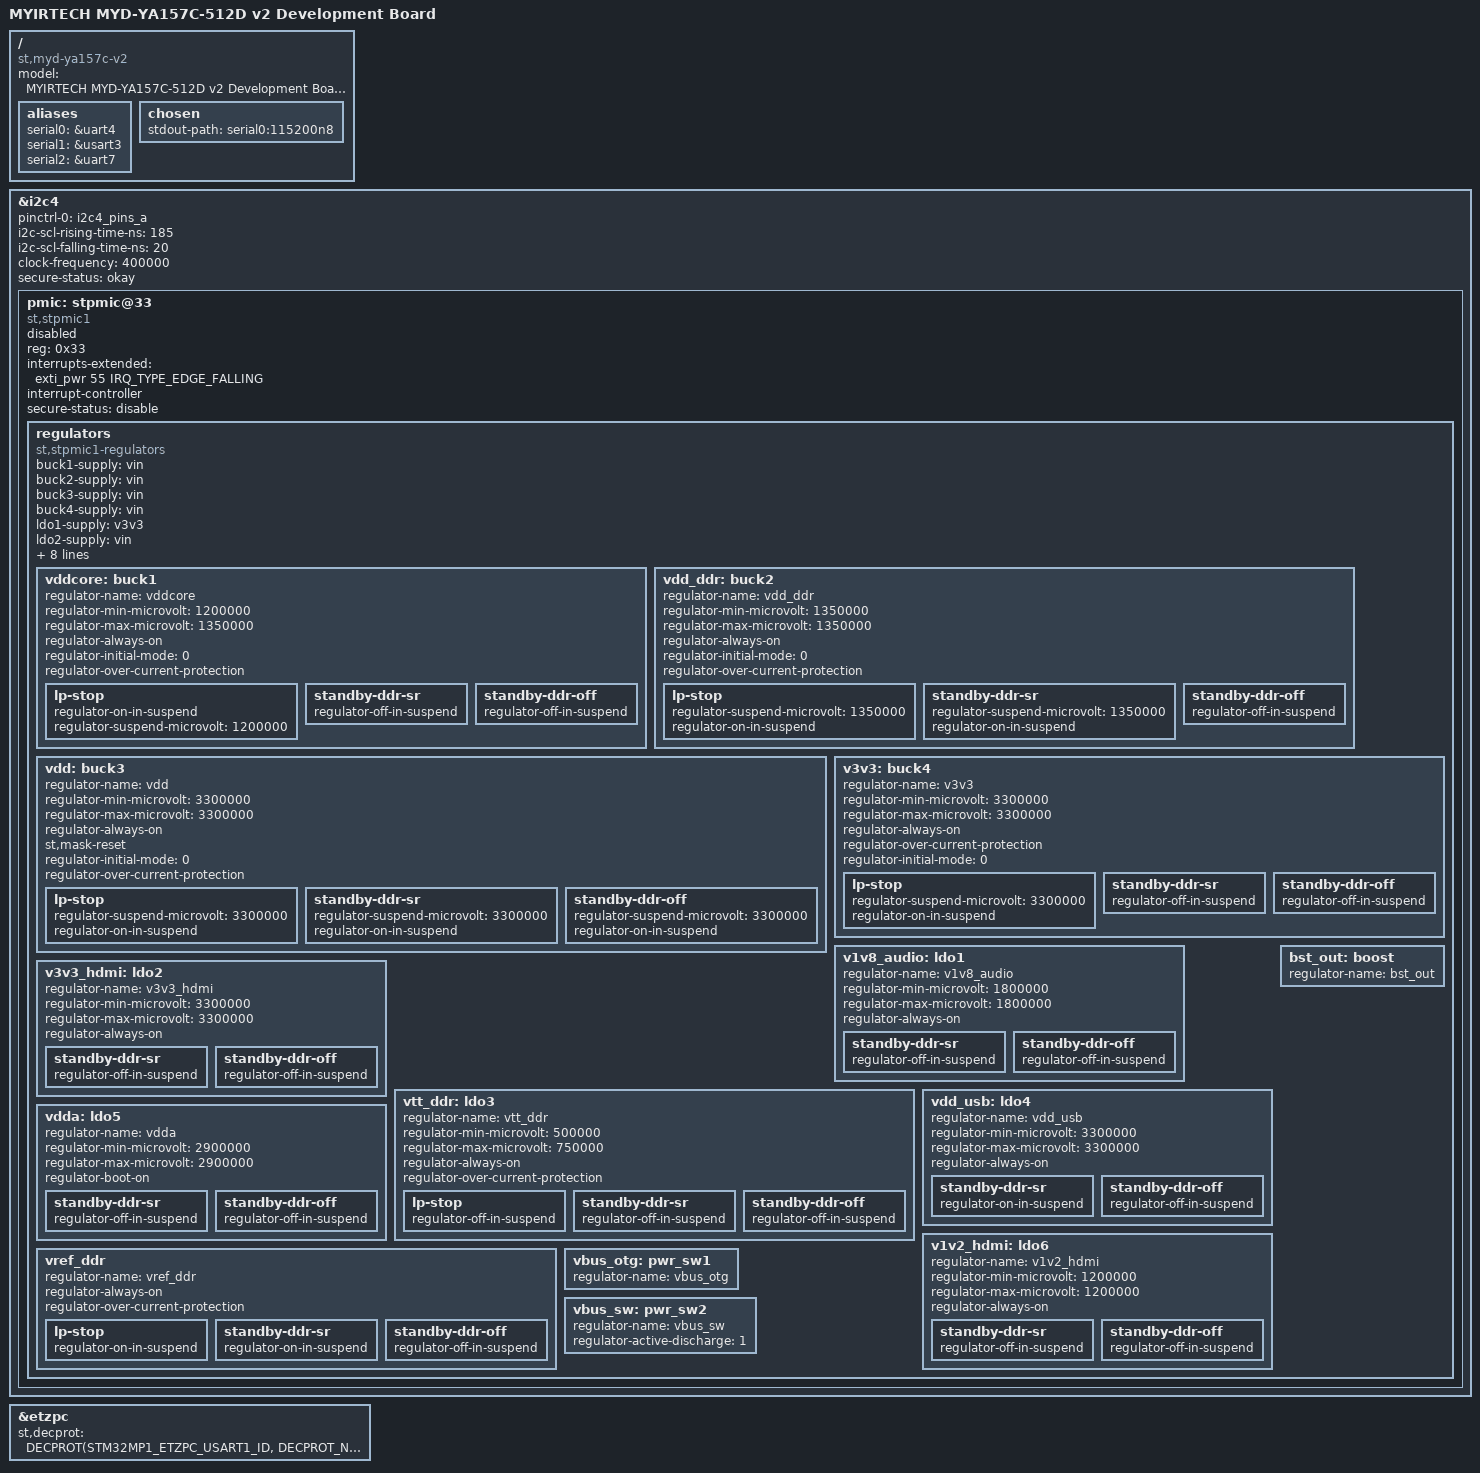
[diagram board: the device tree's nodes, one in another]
// SPDX-License-Identifier: (GPL-2.0+ OR BSD-3-Clause)


/dts-v1/;

#include "stm32mp157.dtsi"
#include "stm32mp15xa.dtsi"
#include "stm32mp15-pinctrl.dtsi"
#include "stm32mp15xxac-pinctrl.dtsi"
#include <dt-bindings/soc/st,stm32-etzpc.h>
#include "stm32mp15xx-ya157c.dtsi"

/ {
	model = "MYIRTECH MYD-YA157C-512D v2 Development Board";
	compatible = "st,myd-ya157c-v2", "st,stm32mp157";
	
	aliases {
		serial0 = &uart4;
		serial1 = &usart3;
		serial2 = &uart7;
	};

	chosen {
		stdout-path = "serial0:115200n8";
	};

};

&i2c4 {
	pinctrl-names = "default";
	pinctrl-0 = <&i2c4_pins_a>;
	i2c-scl-rising-time-ns = <185>;
	i2c-scl-falling-time-ns = <20>;
	clock-frequency = <400000>;
	status = "okay";
	secure-status = "okay";

	pmic: stpmic@33 {
		compatible = "st,stpmic1";
		reg = <0x33>;
		interrupts-extended = <&exti_pwr 55 IRQ_TYPE_EDGE_FALLING>;
		interrupt-controller;
		#interrupt-cells = <2>;
		status = "disable";
		secure-status = "disable";

		regulators {
			compatible = "st,stpmic1-regulators";
			buck1-supply = <&vin>;
			buck2-supply = <&vin>;
			buck3-supply = <&vin>;
			buck4-supply = <&vin>;
			ldo1-supply = <&v3v3>;
			ldo2-supply = <&vin>;
			ldo3-supply = <&vdd_ddr>;
			ldo4-supply = <&vin>;
			ldo5-supply = <&vin>;
			ldo6-supply = <&v3v3>;
			vref_ddr-supply = <&vin>;
			boost-supply = <&vin>;
			pwr_sw1-supply = <&bst_out>;
			pwr_sw2-supply = <&bst_out>;

			vddcore: buck1 {
				regulator-name = "vddcore";
				regulator-min-microvolt = <1200000>;
				regulator-max-microvolt = <1350000>;
				regulator-always-on;
				regulator-initial-mode = <0>;
				regulator-over-current-protection;
				lp-stop {
					regulator-on-in-suspend;
					regulator-suspend-microvolt = <1200000>;
				};
				standby-ddr-sr {
					regulator-off-in-suspend;
				};
				standby-ddr-off {
					regulator-off-in-suspend;
				};
			};

			vdd_ddr: buck2 {
				regulator-name = "vdd_ddr";
				regulator-min-microvolt = <1350000>;
				regulator-max-microvolt = <1350000>;
				regulator-always-on;
				regulator-initial-mode = <0>;
				regulator-over-current-protection;
				lp-stop {
					regulator-suspend-microvolt = <1350000>;
					regulator-on-in-suspend;
				};
				standby-ddr-sr {
					regulator-suspend-microvolt = <1350000>;
					regulator-on-in-suspend;
				};
				standby-ddr-off {
					regulator-off-in-suspend;
				};
			};

			vdd: buck3 {
				regulator-name = "vdd";
				regulator-min-microvolt = <3300000>;
				regulator-max-microvolt = <3300000>;
				regulator-always-on;
				st,mask-reset;
				regulator-initial-mode = <0>;
				regulator-over-current-protection;
				lp-stop {
					regulator-suspend-microvolt = <3300000>;
					regulator-on-in-suspend;
				};
				standby-ddr-sr {
					regulator-suspend-microvolt = <3300000>;
					regulator-on-in-suspend;
				};
				standby-ddr-off {
					regulator-suspend-microvolt = <3300000>;
					regulator-on-in-suspend;
				};
			};

			v3v3: buck4 {
				regulator-name = "v3v3";
				regulator-min-microvolt = <3300000>;
				regulator-max-microvolt = <3300000>;
				regulator-always-on;
				regulator-over-current-protection;
				regulator-initial-mode = <0>;
				lp-stop {
					regulator-suspend-microvolt = <3300000>;
					regulator-on-in-suspend;
				};
				standby-ddr-sr {
					regulator-off-in-suspend;
				};
				standby-ddr-off {
					regulator-off-in-suspend;
				};
			};

			v1v8_audio: ldo1 {
				regulator-name = "v1v8_audio";
				regulator-min-microvolt = <1800000>;
				regulator-max-microvolt = <1800000>;
				regulator-always-on;
				standby-ddr-sr {
					regulator-off-in-suspend;
				};
				standby-ddr-off {
					regulator-off-in-suspend;
				};
			};

			v3v3_hdmi: ldo2 {
				regulator-name = "v3v3_hdmi";
				regulator-min-microvolt = <3300000>;
				regulator-max-microvolt = <3300000>;
				regulator-always-on;
				standby-ddr-sr {
					regulator-off-in-suspend;
				};
				standby-ddr-off {
					regulator-off-in-suspend;
				};
			};

			vtt_ddr: ldo3 {
				regulator-name = "vtt_ddr";
				regulator-min-microvolt = <500000>;
				regulator-max-microvolt = <750000>;
				regulator-always-on;
				regulator-over-current-protection;
				lp-stop {
					regulator-off-in-suspend;
				};
				standby-ddr-sr {
					regulator-off-in-suspend;
				};
				standby-ddr-off {
					regulator-off-in-suspend;
				};
			};

			vdd_usb: ldo4 {
				regulator-name = "vdd_usb";
				regulator-min-microvolt = <3300000>;
				regulator-max-microvolt = <3300000>;
				regulator-always-on;
				standby-ddr-sr {
					regulator-on-in-suspend;
				};
				standby-ddr-off {
					regulator-off-in-suspend;
				};
			};

			vdda: ldo5 {
				regulator-name = "vdda";
				regulator-min-microvolt = <2900000>;
				regulator-max-microvolt = <2900000>;
				regulator-boot-on;
				standby-ddr-sr {
					regulator-off-in-suspend;
				};
				standby-ddr-off {
					regulator-off-in-suspend;
				};
			};

			v1v2_hdmi: ldo6 {
				regulator-name = "v1v2_hdmi";
				regulator-min-microvolt = <1200000>;
				regulator-max-microvolt = <1200000>;
				regulator-always-on;
				standby-ddr-sr {
					regulator-off-in-suspend;
				};
				standby-ddr-off {
					regulator-off-in-suspend;
				};
			};

			vref_ddr: vref_ddr {
				regulator-name = "vref_ddr";
				regulator-always-on;
				regulator-over-current-protection;
				lp-stop {
					regulator-on-in-suspend;
				};
				standby-ddr-sr {
					regulator-on-in-suspend;
				};
				standby-ddr-off {
					regulator-off-in-suspend;
				};
			};

			bst_out: boost {
				regulator-name = "bst_out";
			};

			vbus_otg: pwr_sw1 {
				regulator-name = "vbus_otg";
			};

			vbus_sw: pwr_sw2 {
				regulator-name = "vbus_sw";
				regulator-active-discharge = <1>;
			};
		};
	};
};
&etzpc {
	st,decprot = <
		DECPROT(STM32MP1_ETZPC_USART1_ID, DECPROT_NS_RW, DECPROT_UNLOCK)
		DECPROT(STM32MP1_ETZPC_SPI6_ID, DECPROT_NS_RW, DECPROT_UNLOCK)
		DECPROT(STM32MP1_ETZPC_I2C4_ID, DECPROT_NS_RW, DECPROT_UNLOCK)
		DECPROT(STM32MP1_ETZPC_I2C6_ID, DECPROT_NS_RW, DECPROT_UNLOCK)
		DECPROT(STM32MP1_ETZPC_RNG1_ID, DECPROT_NS_RW, DECPROT_UNLOCK)
		DECPROT(STM32MP1_ETZPC_HASH1_ID, DECPROT_NS_RW, DECPROT_UNLOCK)
		DECPROT(STM32MP1_ETZPC_DDRCTRL_ID, DECPROT_S_RW, DECPROT_LOCK)
		DECPROT(STM32MP1_ETZPC_DDRPHYC_ID, DECPROT_S_RW, DECPROT_LOCK)
		DECPROT(STM32MP1_ETZPC_STGENC_ID, DECPROT_S_RW, DECPROT_LOCK)
		DECPROT(STM32MP1_ETZPC_BKPSRAM_ID, DECPROT_S_RW, DECPROT_LOCK)
		DECPROT(STM32MP1_ETZPC_IWDG1_ID, DECPROT_S_RW, DECPROT_LOCK)
	>;
};


